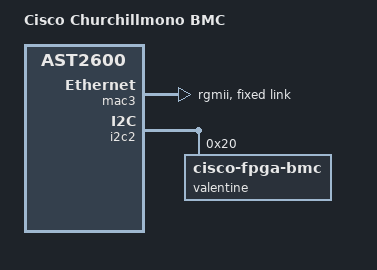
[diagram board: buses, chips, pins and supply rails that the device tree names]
// SPDX-License-Identifier: GPL-2.0+
// Copyright (c) 2022 Cisco Systems Inc.
// Copyright (c) Meta Platforms, Inc. and affiliates.

/dts-v1/;

#include "ast2600-facebook-netbmc-common.dtsi"

/ {
	model = "Cisco Churchillmono BMC";
	compatible = "cisco,churchillmono-bmc", "aspeed,ast2600";

	spi_gpio: spi-gpio {
		num-chipselects = <2>;
		cs-gpios = <&gpio0 ASPEED_GPIO(X, 0) GPIO_ACTIVE_LOW>,
			   <&gpio0 ASPEED_GPIO(X, 1) GPIO_ACTIVE_HIGH>;
	};
};

&mac3 {
	status = "okay";
	pinctrl-names = "default";
	pinctrl-0 = <&pinctrl_rgmii4_default>;
	phy-mode = "rgmii";
	fixed-link {
		speed = <1000>;
		full-duplex;
	};
};

&emmc {
	clk-phase-legacy = <180 180>;
	clk-phase-mmc-hs = <180 180>;
	clk-phase-mmc-hs200 = <180 180>;
	clk-phase-mmc-hs400 = <180 180>;
};

&i2c2 {
	bus-frequency = <1000000>;

	valentine@20 {
		compatible = "cisco-fpga-bmc";
		reg = <0x20>;
		devid-none = <1>;
#include "cisco-valentine.dtsi"
	};
};

